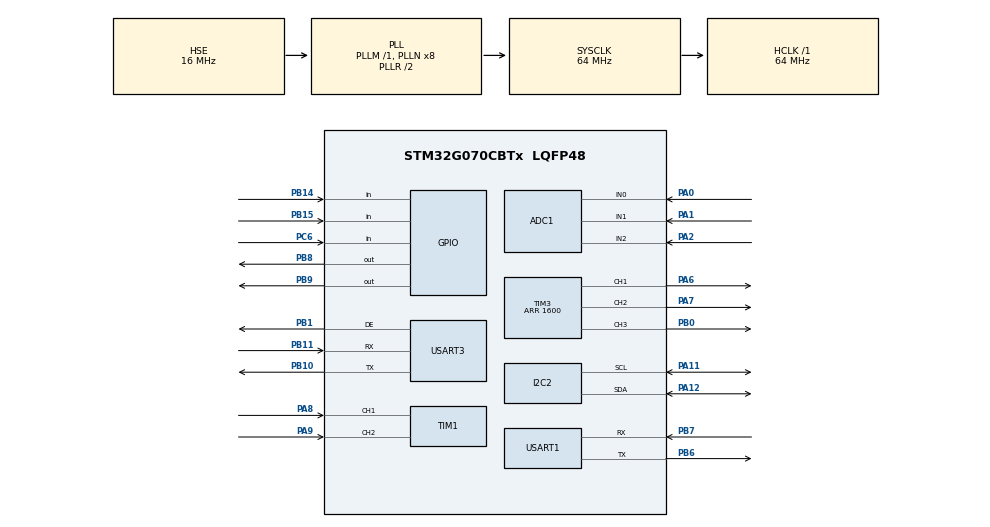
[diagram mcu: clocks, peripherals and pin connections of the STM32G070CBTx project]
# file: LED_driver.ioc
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ADC1.Channel-0\#ChannelRegularConversion=ADC_CHANNEL_0
ADC1.NbrOfConversionFlag=1
ADC1.Rank-0\#ChannelRegularConversion=1
ADC1.SamplingTime-0\#ChannelRegularConversion=ADC_SAMPLINGTIME_COMMON_1
ADC1.SelectedChannel=ADC_CHANNEL_0|ADC_CHANNEL_1|ADC_CHANNEL_2
ADC1.master=1
FREERTOS.Tasks01=mainTask,24,256,StartMainTask,As weak,NULL,Static,mainTaskBuffer,mainTaskControlBlock
FREERTOS.configUSE_NEWLIB_REENTRANT=1
I2C2.Timing=0x10B17DB5
Mcu.Family=STM32G0
Mcu.Name=STM32G070CBTx
Mcu.Package=LQFP48
NVIC.TIM7_IRQn=true\:3\:0\:false\:false\:true\:false\:false\:true\:true
NVIC.TimeBase=TIM7_IRQn
NVIC.TimeBaseIP=TIM7
PA0.Mode=IN0
PA0.Signal=ADC1_IN0
PA1.Mode=IN1
PA1.Signal=ADC1_IN1
PA11\ [PA9].Mode=I2C
PA11\ [PA9].Signal=I2C2_SCL
PA12\ [PA10].Mode=I2C
PA12\ [PA10].Signal=I2C2_SDA
PA13.Mode=Serial_Wire
PA13.Signal=SYS_SWDIO
PA14-BOOT0.Mode=Serial_Wire
PA14-BOOT0.Signal=SYS_SWCLK
PA2.Mode=IN2
PA2.Signal=ADC1_IN2
PA6.Signal=S_TIM3_CH1
PA7.Signal=S_TIM3_CH2
PA8.Signal=S_TIM1_CH1
PA9.Signal=S_TIM1_CH2
PB0.Signal=S_TIM3_CH3
PB1.Mode=Hardware Flow Control (RS485)
PB1.Signal=USART3_DE
PB10.Mode=Asynchronous
PB10.Signal=USART3_TX
PB11.Mode=Asynchronous
PB11.Signal=USART3_RX
PB14.Signal=GPIO_Input
PB15.Signal=GPIO_Input
PB6.Mode=Asynchronous
PB6.Signal=USART1_TX
PB7.Mode=Asynchronous
PB7.Signal=USART1_RX
PB8.Signal=GPIO_Output
PB9.Signal=GPIO_Output
PC6.Signal=GPIO_Input
PF0-OSC_IN\ (PF0).Mode=HSE-External-Oscillator
PF0-OSC_IN\ (PF0).Signal=RCC_OSC_IN
PF1-OSC_OUT\ (PF1).Mode=HSE-External-Oscillator
PF1-OSC_OUT\ (PF1).Signal=RCC_OSC_OUT
ProjectManager.HeapSize=0x200
ProjectManager.StackSize=0x400
ProjectManager.TargetToolchain=Makefile
RCC.ADCFreq_Value=64000000
RCC.AHBFreq_Value=64000000
RCC.CortexFreq_Value=64000000
RCC.EXTERNAL_CLOCK_VALUE=48000
RCC.HCLKFreq_Value=64000000
RCC.HSE_VALUE=16000000
RCC.HSI_VALUE=16000000
RCC.LSE_VALUE=32768
RCC.PLLSourceVirtual=RCC_PLLSOURCE_HSE
RCC.SYSCLKFreq_VALUE=64000000
RCC.SYSCLKSource=RCC_SYSCLKSOURCE_PLLCLK
RCC.VCOOutputFreq_Value=128000000
SH.S_TIM1_CH1.0=TIM1_CH1,Encoder_Interface
SH.S_TIM1_CH2.0=TIM1_CH2,Encoder_Interface
SH.S_TIM3_CH1.0=TIM3_CH1,PWM Generation1 CH1
SH.S_TIM3_CH2.0=TIM3_CH2,PWM Generation2 CH2
SH.S_TIM3_CH3.0=TIM3_CH3,PWM Generation3 CH3
TIM3.Channel-PWM\ Generation1\ CH1=TIM_CHANNEL_1
TIM3.Channel-PWM\ Generation2\ CH2=TIM_CHANNEL_2
TIM3.Channel-PWM\ Generation3\ CH3=TIM_CHANNEL_3
TIM3.Period=1600
TIM3.Pulse-PWM\ Generation1\ CH1=800
TIM3.Pulse-PWM\ Generation2\ CH2=200
TIM3.Pulse-PWM\ Generation3\ CH3=1400
USART1.FIFOMode=FIFOMODE_ENABLE
USART1.VirtualMode-Asynchronous=VM_ASYNC
USART3.VirtualMode-Asynchronous=VM_ASYNC
USART3.VirtualMode-Hardware\ Flow\ Control\ (RS485)=VM_ASYNC
VP_FREERTOS_VS_CMSIS_V2.Mode=CMSIS_V2
VP_SYS_VS_DBSignals.Mode=DisableDeadBatterySignals
VP_SYS_VS_tim7.Mode=TIM7
VP_TIM3_VS_ClockSourceINT.Mode=Internal
board=custom

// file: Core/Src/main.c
/* USER CODE BEGIN Header */
/**
  ******************************************************************************
  * @file           : main.c
  * @brief          : Main program body
  ******************************************************************************
  * @attention
  *
  * Copyright (c) 2024 STMicroelectronics.
  * All rights reserved.
  *
  * This software is licensed under terms that can be found in the LICENSE file
  * in the root directory of this software component.
  * If no LICENSE file comes with this software, it is provided AS-IS.
  *
  ******************************************************************************
  */
/* USER CODE END Header */
#include "main.h"
#include "cmsis_os.h"

/* USER CODE BEGIN Includes */
#include "my_main.hpp"
/* USER CODE END Includes */

typedef StaticTask_t osStaticThreadDef_t;

ADC_HandleTypeDef hadc1;

I2C_HandleTypeDef hi2c2;

TIM_HandleTypeDef htim1;
TIM_HandleTypeDef htim3;

UART_HandleTypeDef huart1;
UART_HandleTypeDef huart3;

/* Definitions for mainTask */
osThreadId_t mainTaskHandle;
uint32_t mainTaskBuffer[ 256 ];
osStaticThreadDef_t mainTaskControlBlock;
const osThreadAttr_t mainTask_attributes = {
  .name = "mainTask",
  .stack_mem = &mainTaskBuffer[0],
  .stack_size = sizeof(mainTaskBuffer),
  .cb_mem = &mainTaskControlBlock,
  .cb_size = sizeof(mainTaskControlBlock),
  .priority = (osPriority_t) osPriorityNormal,
};

void SystemClock_Config(void);
static void MX_GPIO_Init(void);
static void MX_ADC1_Init(void);
static void MX_I2C2_Init(void);
static void MX_TIM1_Init(void);
static void MX_TIM3_Init(void);
static void MX_USART3_UART_Init(void);
static void MX_USART1_UART_Init(void);
void StartMainTask(void *argument);

int main(void)
{

  /* MCU Configuration--------------------------------------------------------*/

  /* Reset of all peripherals, Initializes the Flash interface and the Systick. */
  HAL_Init();

  /* Configure the system clock */
  SystemClock_Config();

  /* Initialize all configured peripherals */
  MX_GPIO_Init();
  MX_ADC1_Init();
  MX_I2C2_Init();
  MX_TIM1_Init();
  MX_TIM3_Init();
  MX_USART3_UART_Init();
  MX_USART1_UART_Init();

  /* Init scheduler */
  osKernelInitialize();

  /* Create the thread(s) */
  /* creation of mainTask */
  mainTaskHandle = osThreadNew(StartMainTask, NULL, &mainTask_attributes);

  /* Start scheduler */
  osKernelStart();

  /* We should never get here as control is now taken by the scheduler */

  /* Infinite loop */
  while (1)
  {

  }
}

void SystemClock_Config(void)
{
  RCC_OscInitTypeDef RCC_OscInitStruct = {0};
  RCC_ClkInitTypeDef RCC_ClkInitStruct = {0};

  /** Configure the main internal regulator output voltage
  */
  HAL_PWREx_ControlVoltageScaling(PWR_REGULATOR_VOLTAGE_SCALE1);

  /** Initializes the RCC Oscillators according to the specified parameters
  * in the RCC_OscInitTypeDef structure.
  */
  RCC_OscInitStruct.OscillatorType = RCC_OSCILLATORTYPE_HSE;
  RCC_OscInitStruct.HSEState = RCC_HSE_ON;
  RCC_OscInitStruct.PLL.PLLState = RCC_PLL_ON;
  RCC_OscInitStruct.PLL.PLLSource = RCC_PLLSOURCE_HSE;
  RCC_OscInitStruct.PLL.PLLM = RCC_PLLM_DIV1;
  RCC_OscInitStruct.PLL.PLLN = 8;
  RCC_OscInitStruct.PLL.PLLP = RCC_PLLP_DIV2;
  RCC_OscInitStruct.PLL.PLLR = RCC_PLLR_DIV2;
  if (HAL_RCC_OscConfig(&RCC_OscInitStruct) != HAL_OK)
  {
    Error_Handler();
  }

  /** Initializes the CPU, AHB and APB buses clocks
  */
  RCC_ClkInitStruct.ClockType = RCC_CLOCKTYPE_HCLK|RCC_CLOCKTYPE_SYSCLK
                              |RCC_CLOCKTYPE_PCLK1;
  RCC_ClkInitStruct.SYSCLKSource = RCC_SYSCLKSOURCE_PLLCLK;
  RCC_ClkInitStruct.AHBCLKDivider = RCC_SYSCLK_DIV1;
  RCC_ClkInitStruct.APB1CLKDivider = RCC_HCLK_DIV1;

  if (HAL_RCC_ClockConfig(&RCC_ClkInitStruct, FLASH_LATENCY_2) != HAL_OK)
  {
    Error_Handler();
  }
}

static void MX_ADC1_Init(void)
{

  ADC_ChannelConfTypeDef sConfig = {0};

  /** Configure the global features of the ADC (Clock, Resolution, Data Alignment and number of conversion)
  */
  hadc1.Instance = ADC1;
  hadc1.Init.ClockPrescaler = ADC_CLOCK_SYNC_PCLK_DIV2;
  hadc1.Init.Resolution = ADC_RESOLUTION_12B;
  hadc1.Init.DataAlign = ADC_DATAALIGN_RIGHT;
  hadc1.Init.ScanConvMode = ADC_SCAN_DISABLE;
  hadc1.Init.EOCSelection = ADC_EOC_SINGLE_CONV;
  hadc1.Init.LowPowerAutoWait = DISABLE;
  hadc1.Init.LowPowerAutoPowerOff = DISABLE;
  hadc1.Init.ContinuousConvMode = DISABLE;
  hadc1.Init.NbrOfConversion = 1;
  hadc1.Init.DiscontinuousConvMode = DISABLE;
  hadc1.Init.ExternalTrigConv = ADC_SOFTWARE_START;
  hadc1.Init.ExternalTrigConvEdge = ADC_EXTERNALTRIGCONVEDGE_NONE;
  hadc1.Init.DMAContinuousRequests = DISABLE;
  hadc1.Init.Overrun = ADC_OVR_DATA_PRESERVED;
  hadc1.Init.SamplingTimeCommon1 = ADC_SAMPLETIME_1CYCLE_5;
  hadc1.Init.SamplingTimeCommon2 = ADC_SAMPLETIME_1CYCLE_5;
  hadc1.Init.OversamplingMode = DISABLE;
  hadc1.Init.TriggerFrequencyMode = ADC_TRIGGER_FREQ_HIGH;
  if (HAL_ADC_Init(&hadc1) != HAL_OK)
  {
    Error_Handler();
  }

  /** Configure Regular Channel
  */
  sConfig.Channel = ADC_CHANNEL_0;
  sConfig.Rank = ADC_REGULAR_RANK_1;
  sConfig.SamplingTime = ADC_SAMPLINGTIME_COMMON_1;
  if (HAL_ADC_ConfigChannel(&hadc1, &sConfig) != HAL_OK)
  {
    Error_Handler();
  }

}

static void MX_I2C2_Init(void)
{

  hi2c2.Instance = I2C2;
  hi2c2.Init.Timing = 0x10B17DB5;
  hi2c2.Init.OwnAddress1 = 0;
  hi2c2.Init.AddressingMode = I2C_ADDRESSINGMODE_7BIT;
  hi2c2.Init.DualAddressMode = I2C_DUALADDRESS_DISABLE;
  hi2c2.Init.OwnAddress2 = 0;
  hi2c2.Init.OwnAddress2Masks = I2C_OA2_NOMASK;
  hi2c2.Init.GeneralCallMode = I2C_GENERALCALL_DISABLE;
  hi2c2.Init.NoStretchMode = I2C_NOSTRETCH_DISABLE;
  if (HAL_I2C_Init(&hi2c2) != HAL_OK)
  {
    Error_Handler();
  }

  /** Configure Analogue filter
  */
  if (HAL_I2CEx_ConfigAnalogFilter(&hi2c2, I2C_ANALOGFILTER_ENABLE) != HAL_OK)
  {
    Error_Handler();
  }

  /** Configure Digital filter
  */
  if (HAL_I2CEx_ConfigDigitalFilter(&hi2c2, 0) != HAL_OK)
  {
    Error_Handler();
  }

}

static void MX_TIM1_Init(void)
{

  TIM_Encoder_InitTypeDef sConfig = {0};
  TIM_MasterConfigTypeDef sMasterConfig = {0};

  htim1.Instance = TIM1;
  htim1.Init.Prescaler = 0;
  htim1.Init.CounterMode = TIM_COUNTERMODE_UP;
  htim1.Init.Period = 65535;
  htim1.Init.ClockDivision = TIM_CLOCKDIVISION_DIV1;
  htim1.Init.RepetitionCounter = 0;
  htim1.Init.AutoReloadPreload = TIM_AUTORELOAD_PRELOAD_DISABLE;
  sConfig.EncoderMode = TIM_ENCODERMODE_TI1;
  sConfig.IC1Polarity = TIM_ICPOLARITY_RISING;
  sConfig.IC1Selection = TIM_ICSELECTION_DIRECTTI;
  sConfig.IC1Prescaler = TIM_ICPSC_DIV1;
  sConfig.IC1Filter = 0;
  sConfig.IC2Polarity = TIM_ICPOLARITY_RISING;
  sConfig.IC2Selection = TIM_ICSELECTION_DIRECTTI;
  sConfig.IC2Prescaler = TIM_ICPSC_DIV1;
  sConfig.IC2Filter = 0;
  if (HAL_TIM_Encoder_Init(&htim1, &sConfig) != HAL_OK)
  {
    Error_Handler();
  }
  sMasterConfig.MasterOutputTrigger = TIM_TRGO_RESET;
  sMasterConfig.MasterOutputTrigger2 = TIM_TRGO2_RESET;
  sMasterConfig.MasterSlaveMode = TIM_MASTERSLAVEMODE_DISABLE;
  if (HAL_TIMEx_MasterConfigSynchronization(&htim1, &sMasterConfig) != HAL_OK)
  {
    Error_Handler();
  }

}

static void MX_TIM3_Init(void)
{

  TIM_ClockConfigTypeDef sClockSourceConfig = {0};
  TIM_MasterConfigTypeDef sMasterConfig = {0};
  TIM_OC_InitTypeDef sConfigOC = {0};

  htim3.Instance = TIM3;
  htim3.Init.Prescaler = 0;
  htim3.Init.CounterMode = TIM_COUNTERMODE_UP;
  htim3.Init.Period = 1600;
  htim3.Init.ClockDivision = TIM_CLOCKDIVISION_DIV1;
  htim3.Init.AutoReloadPreload = TIM_AUTORELOAD_PRELOAD_DISABLE;
  if (HAL_TIM_Base_Init(&htim3) != HAL_OK)
  {
    Error_Handler();
  }
  sClockSourceConfig.ClockSource = TIM_CLOCKSOURCE_INTERNAL;
  if (HAL_TIM_ConfigClockSource(&htim3, &sClockSourceConfig) != HAL_OK)
  {
    Error_Handler();
  }
  if (HAL_TIM_PWM_Init(&htim3) != HAL_OK)
  {
    Error_Handler();
  }
  sMasterConfig.MasterOutputTrigger = TIM_TRGO_RESET;
  sMasterConfig.MasterSlaveMode = TIM_MASTERSLAVEMODE_DISABLE;
  if (HAL_TIMEx_MasterConfigSynchronization(&htim3, &sMasterConfig) != HAL_OK)
  {
    Error_Handler();
  }
  sConfigOC.OCMode = TIM_OCMODE_PWM1;
  sConfigOC.Pulse = 800;
  sConfigOC.OCPolarity = TIM_OCPOLARITY_HIGH;
  sConfigOC.OCFastMode = TIM_OCFAST_DISABLE;
  if (HAL_TIM_PWM_ConfigChannel(&htim3, &sConfigOC, TIM_CHANNEL_1) != HAL_OK)
  {
    Error_Handler();
  }
  sConfigOC.Pulse = 200;
  if (HAL_TIM_PWM_ConfigChannel(&htim3, &sConfigOC, TIM_CHANNEL_2) != HAL_OK)
  {
    Error_Handler();
  }
  sConfigOC.Pulse = 1400;
  if (HAL_TIM_PWM_ConfigChannel(&htim3, &sConfigOC, TIM_CHANNEL_3) != HAL_OK)
  {
    Error_Handler();
  }
  HAL_TIM_MspPostInit(&htim3);

}

static void MX_USART1_UART_Init(void)
{

  huart1.Instance = USART1;
  huart1.Init.BaudRate = 115200;
  huart1.Init.WordLength = UART_WORDLENGTH_8B;
  huart1.Init.StopBits = UART_STOPBITS_1;
  huart1.Init.Parity = UART_PARITY_NONE;
  huart1.Init.Mode = UART_MODE_TX_RX;
  huart1.Init.HwFlowCtl = UART_HWCONTROL_NONE;
  huart1.Init.OverSampling = UART_OVERSAMPLING_16;
  huart1.Init.OneBitSampling = UART_ONE_BIT_SAMPLE_DISABLE;
  huart1.Init.ClockPrescaler = UART_PRESCALER_DIV1;
  huart1.AdvancedInit.AdvFeatureInit = UART_ADVFEATURE_NO_INIT;
  if (HAL_UART_Init(&huart1) != HAL_OK)
  {
    Error_Handler();
  }
  if (HAL_UARTEx_SetTxFifoThreshold(&huart1, UART_TXFIFO_THRESHOLD_1_8) != HAL_OK)
  {
    Error_Handler();
  }
  if (HAL_UARTEx_SetRxFifoThreshold(&huart1, UART_RXFIFO_THRESHOLD_1_8) != HAL_OK)
  {
    Error_Handler();
  }
  if (HAL_UARTEx_EnableFifoMode(&huart1) != HAL_OK)
  {
    Error_Handler();
  }

}

static void MX_USART3_UART_Init(void)
{

  huart3.Instance = USART3;
  huart3.Init.BaudRate = 115200;
  huart3.Init.WordLength = UART_WORDLENGTH_8B;
  huart3.Init.StopBits = UART_STOPBITS_1;
  huart3.Init.Parity = UART_PARITY_NONE;
  huart3.Init.Mode = UART_MODE_TX_RX;
  huart3.Init.HwFlowCtl = UART_HWCONTROL_NONE;
  huart3.Init.OverSampling = UART_OVERSAMPLING_16;
  huart3.Init.OneBitSampling = UART_ONE_BIT_SAMPLE_DISABLE;
  huart3.Init.ClockPrescaler = UART_PRESCALER_DIV1;
  huart3.AdvancedInit.AdvFeatureInit = UART_ADVFEATURE_NO_INIT;
  if (HAL_RS485Ex_Init(&huart3, UART_DE_POLARITY_HIGH, 0, 0) != HAL_OK)
  {
    Error_Handler();
  }

}

static void MX_GPIO_Init(void)
{
  GPIO_InitTypeDef GPIO_InitStruct = {0};

  /* GPIO Ports Clock Enable */
  __HAL_RCC_GPIOF_CLK_ENABLE();
  __HAL_RCC_GPIOA_CLK_ENABLE();
  __HAL_RCC_GPIOB_CLK_ENABLE();
  __HAL_RCC_GPIOC_CLK_ENABLE();

  /*Configure GPIO pin Output Level */
  HAL_GPIO_WritePin(GPIOB, GPIO_PIN_8|GPIO_PIN_9, GPIO_PIN_RESET);

  /*Configure GPIO pins : PB14 PB15 */
  GPIO_InitStruct.Pin = GPIO_PIN_14|GPIO_PIN_15;
  GPIO_InitStruct.Mode = GPIO_MODE_INPUT;
  GPIO_InitStruct.Pull = GPIO_NOPULL;
  HAL_GPIO_Init(GPIOB, &GPIO_InitStruct);

  /*Configure GPIO pin : PC6 */
  GPIO_InitStruct.Pin = GPIO_PIN_6;
  GPIO_InitStruct.Mode = GPIO_MODE_INPUT;
  GPIO_InitStruct.Pull = GPIO_NOPULL;
  HAL_GPIO_Init(GPIOC, &GPIO_InitStruct);

  /*Configure GPIO pins : PB8 PB9 */
  GPIO_InitStruct.Pin = GPIO_PIN_8|GPIO_PIN_9;
  GPIO_InitStruct.Mode = GPIO_MODE_OUTPUT_PP;
  GPIO_InitStruct.Pull = GPIO_NOPULL;
  GPIO_InitStruct.Speed = GPIO_SPEED_FREQ_LOW;
  HAL_GPIO_Init(GPIOB, &GPIO_InitStruct);

}

__weak void StartMainTask(void *argument)
{
  for(;;)
  {
    osDelay(1);
  }
}

void HAL_TIM_PeriodElapsedCallback(TIM_HandleTypeDef *htim)
{
  if (htim->Instance == TIM7) {
    HAL_IncTick();
  }
}

void Error_Handler(void)
{
  __disable_irq();
  while (1)
  {
  }
}
